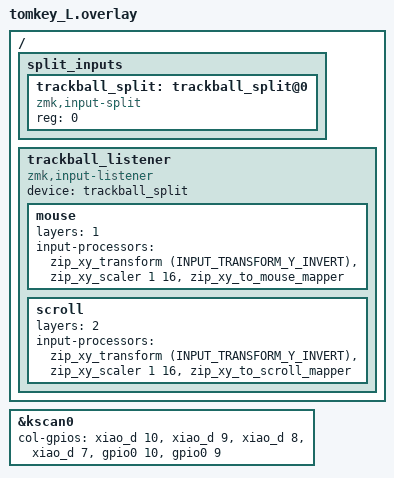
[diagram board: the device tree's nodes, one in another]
#include "tomkey.dtsi"
#include <dt-bindings/zmk/input_transform.h>
#include <input/processors.dtsi>
#include <zephyr/dt-bindings/input/input-event-codes.h>

/ {
    split_inputs {
        #address-cells = <1>;
        #size-cells = <0>;

        trackball_split: trackball_split@0 {
            compatible = "zmk,input-split";
            reg = <0>;
        };
    };

    trackball_listener: trackball_listener {
        compatible = "zmk,input-listener";
        status = "disabled";
        device = <&trackball_split>;
    };
};

/* === 切り替えフラグ: 0 = 手動レイヤー運用, 1 = 旧：自動一時レイヤー === */
#define TB_AUTO_TEMP_LAYER 0

&trackball_listener {
    status = "okay";

#if TB_AUTO_TEMP_LAYER
    /* 旧挙動：トラックボール入力で一時的に layer 1 （元に戻す用） */
    input-processors = <&zip_temp_layer 1 400>;
#else
    /* 新挙動：レイヤーボタンで layer 1 に入っている間だけマウス移動 */
    mouse {
        layers = <1>;
        input-processors =
            <&zip_xy_transform (INPUT_TRANSFORM_Y_INVERT)>,
            <&zip_xy_scaler 1 16>,
            <&zip_xy_to_mouse_mapper>;
    };
#endif

    /* 従来どおり：スクロールは layer 2 限定 */
    scroll {
        layers = <2>;
        input-processors =
            <&zip_xy_transform (INPUT_TRANSFORM_Y_INVERT)>,
            <&zip_xy_scaler 1 16>,
            <&zip_xy_to_scroll_mapper>;
    };
};


&kscan0 {
        col-gpios
            = <&xiao_d 10 GPIO_ACTIVE_HIGH>
            , <&xiao_d 9 GPIO_ACTIVE_HIGH>
            , <&xiao_d 8 GPIO_ACTIVE_HIGH>
            , <&xiao_d 7 GPIO_ACTIVE_HIGH>
            , <&gpio0 10 GPIO_ACTIVE_HIGH>
            , <&gpio0 9 GPIO_ACTIVE_HIGH>
            ;
};
